# ATmega128RFA1 register map
Vendor: Atmel; File version: 1.0
CPU: other r0p0, little endian, no MPU, no FPU, 4 interrupt priority bits
Registers are 8-bit, read-write, reset 0x0 unless marked. A register's access mark holds for its fields unless they carry their own. Offsets are from the block's base; [hi:lo] are bit positions; {n}, {i} and the like mark numbered series; 'fields as' and 'values as' point back to an identical list.

## EEPROM
Base 0x0080003F
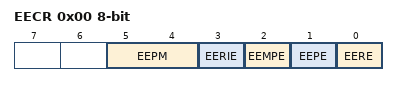
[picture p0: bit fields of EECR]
0x00 EECR — EEPROM Control Register
  [5:4] EEPM — EEPROM Programming Mode
    0=ERASE_AND_WRITE_IN_ONE_OPERATION_ATOMIC_OPERATION; 1=ERASE_ONLY; 2=WRITE_ONLY; 3=RESERVED_FOR_FUTURE_USE
  [3] EERIE — EEPROM Ready Interrupt Enable
  [2] EEMPE — EEPROM Master Write Enable
  [1] EEPE — EEPROM Programming Enable
  [0] EERE — EEPROM Read Enable
0x01 EEDR — EEPROM Data Register
0x02 EEAR 16-bit (reset mask 0xFF) — EEPROM Address Register Bytes

## EXINT — External Interrupts
Base 0x0080003B
0x00 PCIFR — Pin Change Interrupt Flag Register (read-only for debugger)
  [2:0] PCIF — Pin Change Interrupt Flags
0x01 EIFR — External Interrupt Flag Register (read-only for debugger)
  [7:0] INTF — External Interrupt Flag
    0=NO_EDGE_OR_LOGIC_CHANGE_ON_INT7_0_OCCURRED; 1=A_EDGE_OR_LOGIC_CHANGE_ON_INT0_OCCURRED_AND_TRIGGERED_AN_INTERRUPT_REQUEST; 128=A_EDGE_OR_LOGIC_CHANGE_ON_INT7_OCCURRED_AND_TRIGGERED_AN_INTERRUPT_REQUEST
0x02 EIMSK — External Interrupt Mask Register
  [7:0] INT — External Interrupt Request Enable
    0=ALL_EXTERNAL_PIN_INTERRUPTS_ARE_DISABLED; 255=ALL_EXTERNAL_PIN_INTERRUPTS_ARE_ENABLED
0x2D PCICR — Pin Change Interrupt Control Register
  [2:0] PCIE — Pin Change Interrupt Enables
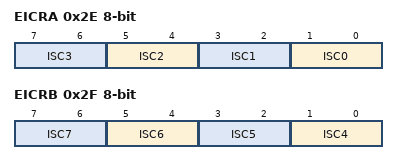
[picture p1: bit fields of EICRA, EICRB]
0x2E EICRA — External Interrupt Control Register A
  [all] fields
    0=THE_LOW_LEVEL_OF_INTN_GENERATES_AN_INTERRUPT_REQUEST; 1=ANY_EDGE_OF_INTN_GENERATES_ASYNCHRONOUSLY_AN_INTERRUPT_REQUEST; 2=THE_FALLING_EDGE_OF_INTN_GENERATES_ASYNCHRONOUSLY_AN_INTERRUPT_REQUEST; 3=THE_RISING_EDGE_OF_INTN_GENERATES_ASYNCHRONOUSLY_AN_INTERRUPT_REQUEST
  [2n+1:2n] ISC{n} (n=0..3) — External Interrupt {n} Sense Control Bit
0x2F EICRB — External Interrupt Control Register B
  [all] fields
    values as the fields of EICRA
  [2n-7:2n-8] ISC{n} (n=4..7) — External Interrupt {n} Sense Control Bit
0x30 PCMSK0 — Pin Change Mask Register 0
0x31 PCMSK1 — Pin Change Mask Register 1
  [7:0] PCINT — Pin Change Enable Mask
0x32 PCMSK2 — Pin Change Mask Register 2
  [7:0] PCINT — Pin Change Enable Mask

## FLASH — FLASH Controller
Base 0x00800067
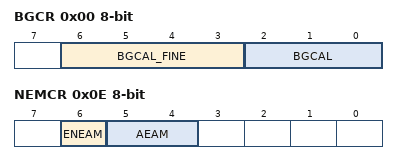
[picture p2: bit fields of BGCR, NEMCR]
0x00 BGCR — Reference Voltage Calibration Register
  [6:3] BGCAL_FINE — Fine Calibration Bits
    0=CENTER_VALUE; 1=VOLTAGE_STEP_UP; 7=SETTING_FOR_HIGHEST_VOLTAGE; 8=VOLTAGE_STEP_DOWN; 15=SETTING_FOR_LOWEST_VOLTAGE
  [2:0] BGCAL — Coarse Calibration Bits
    0=SETTING_FOR_HIGHEST_VOLTAGE; 3=VOLTAGE_STEP_UP; 4=CENTER_VALUE; 5=VOLTAGE_STEP_DOWN; 7=SETTING_FOR_LOWEST_VOLTAGE
0x0E NEMCR — Flash Extended-Mode Control-Register
  [6] ENEAM — Enable Extended Address Mode for Extra Rows
  [5:4] AEAM — Address for Extended Address Mode of Extra Rows
    0=FACTORY_ROW; 1=USER_ROW_1; 2=USER_ROW_2; 3=USER_ROW_3

## JTAG — JTAG Interface
Base 0x00800051
0x00 OCDR — On-Chip Debug Register (write-only for debugger)
  [7:0] OCDR — On-Chip Debug Register Data
    0=REFER_TO_THE_DEBUGGER_DOCUMENTATION_FOR_FURTHER_INFORMATION_ON_HOW_TO_USE_THIS_REGISTER
0x03 MCUSR — MCU Status Register
  [4] JTRF — JTAG Reset Flag
0x04 MCUCR — MCU Control Register
  [7] JTD — JTAG Interface Disable

## PORTA — I/O Port
Base 0x00800020
0x00 PINA — Port A Input Pins Address
0x01 DDRA — Port A Data Direction Register
0x02 PORTA — Port A Data Register

## PORTB — I/O Port
Base 0x00800023
0x00 PINB — Port B Input Pins Address
0x01 DDRB — Port B Data Direction Register
0x02 PORTB — Port B Data Register

## PORTC — I/O Port
Base 0x00800026
0x00 PINC — Port C Input Pins Address
0x01 DDRC — Port C Data Direction Register
0x02 PORTC — Port C Data Register

## PORTD — I/O Port
Base 0x00800029
0x00 PIND — Port D Input Pins Address
0x01 DDRD — Port D Data Direction Register
0x02 PORTD — Port D Data Register
